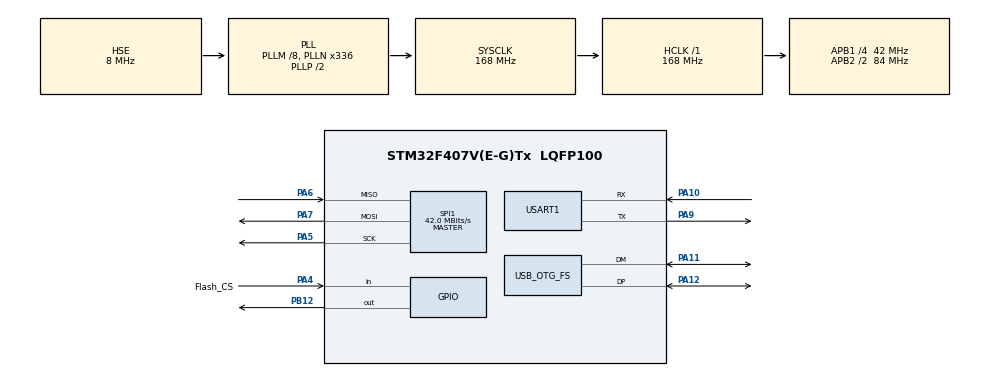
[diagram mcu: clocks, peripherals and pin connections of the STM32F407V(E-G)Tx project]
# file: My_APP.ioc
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FREERTOS.Tasks01=defaultTask,24,128,StartDefaultTask,Default,NULL,Dynamic,NULL,NULL;PIN_B12_Task,8,128,Start_PIN_B12_Task,Default,NULL,Dynamic,NULL,NULL;FeedIWDGTask,8,128,StartFeedIWDG,As external,NULL,Dynamic,NULL,NULL
IWDG.Prescaler=IWDG_PRESCALER_256
Mcu.Family=STM32F4
Mcu.Name=STM32F407V(E-G)Tx
Mcu.Package=LQFP100
NVIC.OTG_FS_IRQn=true\:5\:0\:false\:false\:true\:true\:false\:true\:true
NVIC.PriorityGroup=NVIC_PRIORITYGROUP_4
NVIC.TIM4_IRQn=true\:15\:0\:false\:false\:true\:false\:false\:true\:true
NVIC.TimeBase=TIM4_IRQn
NVIC.TimeBaseIP=TIM4
PA10.Mode=Asynchronous
PA10.Signal=USART1_RX
PA11.Mode=Device_Only
PA11.Signal=USB_OTG_FS_DM
PA12.Mode=Device_Only
PA12.Signal=USB_OTG_FS_DP
PA13.Mode=Serial_Wire
PA13.Signal=SYS_JTMS-SWDIO
PA14.Mode=Serial_Wire
PA14.Signal=SYS_JTCK-SWCLK
PA4.GPIO_Label=Flash_CS
PA4.Signal=GPIO_Input
PA5.Mode=Full_Duplex_Master
PA5.Signal=SPI1_SCK
PA6.Mode=Full_Duplex_Master
PA6.Signal=SPI1_MISO
PA7.Mode=Full_Duplex_Master
PA7.Signal=SPI1_MOSI
PA9.Mode=Asynchronous
PA9.Signal=USART1_TX
PB12.Signal=GPIO_Output
PH0-OSC_IN.Mode=HSE-External-Oscillator
PH0-OSC_IN.Signal=RCC_OSC_IN
PH1-OSC_OUT.Mode=HSE-External-Oscillator
PH1-OSC_OUT.Signal=RCC_OSC_OUT
ProjectManager.HeapSize=0x200
ProjectManager.StackSize=0x400
ProjectManager.TargetToolchain=MDK-ARM V5.32
RCC.48MHZClocksFreq_Value=48000000
RCC.AHBFreq_Value=168000000
RCC.APB1CLKDivider=RCC_HCLK_DIV4
RCC.APB1Freq_Value=42000000
RCC.APB1TimFreq_Value=84000000
RCC.APB2CLKDivider=RCC_HCLK_DIV2
RCC.APB2Freq_Value=84000000
RCC.APB2TimFreq_Value=168000000
RCC.CortexFreq_Value=168000000
RCC.HCLKFreq_Value=168000000
RCC.HSE_VALUE=8000000
RCC.HSI_VALUE=16000000
RCC.LSE_VALUE=32768
RCC.PLLM=8
RCC.PLLN=336
RCC.PLLQ=7
RCC.SYSCLKFreq_VALUE=168000000
RCC.SYSCLKSource=RCC_SYSCLKSOURCE_PLLCLK
RCC.VCOOutputFreq_Value=336000000
SPI1.CLKPhase=SPI_PHASE_2EDGE
SPI1.CLKPolarity=SPI_POLARITY_HIGH
SPI1.CalculateBaudRate=42.0 MBits/s
SPI1.Direction=SPI_DIRECTION_2LINES
SPI1.Mode=SPI_MODE_MASTER
SPI1.VirtualType=VM_MASTER
TIM14.Period=9
TIM14.Prescaler=8400 - 1
USART1.VirtualMode=VM_ASYNC
USB_DEVICE.CLASS_NAME_FS=CDC
USB_DEVICE.VirtualMode-CDC_FS=Cdc
USB_DEVICE.VirtualModeFS=Cdc_FS
USB_OTG_FS.VirtualMode=Device_Only
VP_FREERTOS_VS_CMSIS_V2.Mode=CMSIS_V2
VP_IWDG_VS_IWDG.Mode=IWDG_Activate
VP_SYS_VS_tim4.Mode=TIM4
VP_TIM14_VS_ClockSourceINT.Mode=Enable_Timer
VP_USB_DEVICE_VS_USB_DEVICE_CDC_FS.Mode=CDC_FS
board=custom

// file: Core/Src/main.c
/* USER CODE BEGIN Header */
/**
  ******************************************************************************
  * @file           : main.c
  * @brief          : Main program body
  ******************************************************************************
  * @attention
  *
  * Copyright (c) 2026 STMicroelectronics.
  * All rights reserved.
  *
  * This software is licensed under terms that can be found in the LICENSE file
  * in the root directory of this software component.
  * If no LICENSE file comes with this software, it is provided AS-IS.
  *
  ******************************************************************************
  */
/* USER CODE END Header */
#include "main.h"
#include "cmsis_os.h"
#include "iwdg.h"
#include "spi.h"
#include "tim.h"
#include "usart.h"
#include "usb_device.h"
#include "gpio.h"

/* USER CODE BEGIN Includes */
#include "app_base.h"

/* USER CODE END Includes */

void SystemClock_Config(void);
void MX_FREERTOS_Init(void);

int main(void)
{

  /* MCU Configuration--------------------------------------------------------*/

  /* Reset of all peripherals, Initializes the Flash interface and the Systick. */
  HAL_Init();

  /* Configure the system clock */
  SystemClock_Config();

  /* Initialize all configured peripherals */
  MX_GPIO_Init();
  MX_USART1_UART_Init();
  MX_IWDG_Init();
  MX_SPI1_Init();
  MX_TIM14_Init();
  /* USER CODE BEGIN 2 */
  extern USBD_HandleTypeDef hUsbDeviceFS;
   USBD_CDC_ReceivePacket(&hUsbDeviceFS);

   if(CopyAtoB()!=HAL_OK){
     Send_BootloaderPacket(AllCMDs.AllERRORs->ERROR_Copy_A_To_B,AllBootloaderRunStates.Run_Invalid,NULL);
     BootloaderErrorInterFunc();
     }

  /* USER CODE END 2 */

  /* Init scheduler */
  osKernelInitialize();  /* Call init function for freertos objects (in cmsis_os2.c) */
  MX_FREERTOS_Init();

  /* Start scheduler */
  osKernelStart();

  /* We should never get here as control is now taken by the scheduler */

  /* Infinite loop */
  while (1)
  {

  }
}

void SystemClock_Config(void)
{
  RCC_OscInitTypeDef RCC_OscInitStruct = {0};
  RCC_ClkInitTypeDef RCC_ClkInitStruct = {0};

  /** Configure the main internal regulator output voltage
  */
  __HAL_RCC_PWR_CLK_ENABLE();
  __HAL_PWR_VOLTAGESCALING_CONFIG(PWR_REGULATOR_VOLTAGE_SCALE1);

  /** Initializes the RCC Oscillators according to the specified parameters
  * in the RCC_OscInitTypeDef structure.
  */
  RCC_OscInitStruct.OscillatorType = RCC_OSCILLATORTYPE_LSI|RCC_OSCILLATORTYPE_HSE;
  RCC_OscInitStruct.HSEState = RCC_HSE_ON;
  RCC_OscInitStruct.LSIState = RCC_LSI_ON;
  RCC_OscInitStruct.PLL.PLLState = RCC_PLL_ON;
  RCC_OscInitStruct.PLL.PLLSource = RCC_PLLSOURCE_HSE;
  RCC_OscInitStruct.PLL.PLLM = 8;
  RCC_OscInitStruct.PLL.PLLN = 336;
  RCC_OscInitStruct.PLL.PLLP = RCC_PLLP_DIV2;
  RCC_OscInitStruct.PLL.PLLQ = 7;
  if (HAL_RCC_OscConfig(&RCC_OscInitStruct) != HAL_OK)
  {
    Error_Handler();
  }

  /** Initializes the CPU, AHB and APB buses clocks
  */
  RCC_ClkInitStruct.ClockType = RCC_CLOCKTYPE_HCLK|RCC_CLOCKTYPE_SYSCLK
                              |RCC_CLOCKTYPE_PCLK1|RCC_CLOCKTYPE_PCLK2;
  RCC_ClkInitStruct.SYSCLKSource = RCC_SYSCLKSOURCE_PLLCLK;
  RCC_ClkInitStruct.AHBCLKDivider = RCC_SYSCLK_DIV1;
  RCC_ClkInitStruct.APB1CLKDivider = RCC_HCLK_DIV4;
  RCC_ClkInitStruct.APB2CLKDivider = RCC_HCLK_DIV2;

  if (HAL_RCC_ClockConfig(&RCC_ClkInitStruct, FLASH_LATENCY_5) != HAL_OK)
  {
    Error_Handler();
  }
}

void HAL_TIM_PeriodElapsedCallback(TIM_HandleTypeDef *htim)
{
  if (htim->Instance == TIM4)
  {
    HAL_IncTick();
  }
}

void Error_Handler(void)
{
  __disable_irq();
  while (1)
  {
  }
}

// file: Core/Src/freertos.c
/* USER CODE BEGIN Header */
/**
  ******************************************************************************
  * File Name          : freertos.c
  * Description        : Code for freertos applications
  ******************************************************************************
  * @attention
  *
  * Copyright (c) 2026 STMicroelectronics.
  * All rights reserved.
  *
  * This software is licensed under terms that can be found in the LICENSE file
  * in the root directory of this software component.
  * If no LICENSE file comes with this software, it is provided AS-IS.
  *
  ******************************************************************************
  */
/* USER CODE END Header */

#include "FreeRTOS.h"
#include "task.h"
#include "main.h"
#include "cmsis_os.h"

/* Definitions for defaultTask */
osThreadId_t defaultTaskHandle;
const osThreadAttr_t defaultTask_attributes = {
  .name = "defaultTask",
  .stack_size = 128 * 4,
  .priority = (osPriority_t) osPriorityNormal,
};
/* Definitions for PIN_B12_Task */
osThreadId_t PIN_B12_TaskHandle;
const osThreadAttr_t PIN_B12_Task_attributes = {
  .name = "PIN_B12_Task",
  .stack_size = 128 * 4,
  .priority = (osPriority_t) osPriorityLow,
};
/* Definitions for FeedIWDGTask */
osThreadId_t FeedIWDGTaskHandle;
const osThreadAttr_t FeedIWDGTask_attributes = {
  .name = "FeedIWDGTask",
  .stack_size = 128 * 4,
  .priority = (osPriority_t) osPriorityLow,
};

void StartDefaultTask(void *argument);
void Start_PIN_B12_Task(void *argument);
extern void StartFeedIWDG(void *argument);

extern void MX_USB_DEVICE_Init(void);
void MX_FREERTOS_Init(void); /* (MISRA C 2004 rule 8.1) */

void MX_FREERTOS_Init(void) {

  /* Create the thread(s) */
  /* creation of defaultTask */
  defaultTaskHandle = osThreadNew(StartDefaultTask, NULL, &defaultTask_attributes);

  /* creation of PIN_B12_Task */
  PIN_B12_TaskHandle = osThreadNew(Start_PIN_B12_Task, NULL, &PIN_B12_Task_attributes);

  /* creation of FeedIWDGTask */
  FeedIWDGTaskHandle = osThreadNew(StartFeedIWDG, NULL, &FeedIWDGTask_attributes);

}

void StartDefaultTask(void *argument)
{
  /* init code for USB_DEVICE */
  MX_USB_DEVICE_Init();
  for(;;)
  {
    osDelay(1);
  }
}

void Start_PIN_B12_Task(void *argument)
{
  /* USER CODE BEGIN Start_PIN_B12_Task */
  /* Infinite loop */
  for(;;)
  {
    HAL_GPIO_WritePin(GPIOB,GPIO_PIN_12,GPIO_PIN_SET);
    osDelay(100);
    HAL_GPIO_WritePin(GPIOB,GPIO_PIN_12,GPIO_PIN_RESET);
    osDelay(100);
  }
  /* USER CODE END Start_PIN_B12_Task */
}
